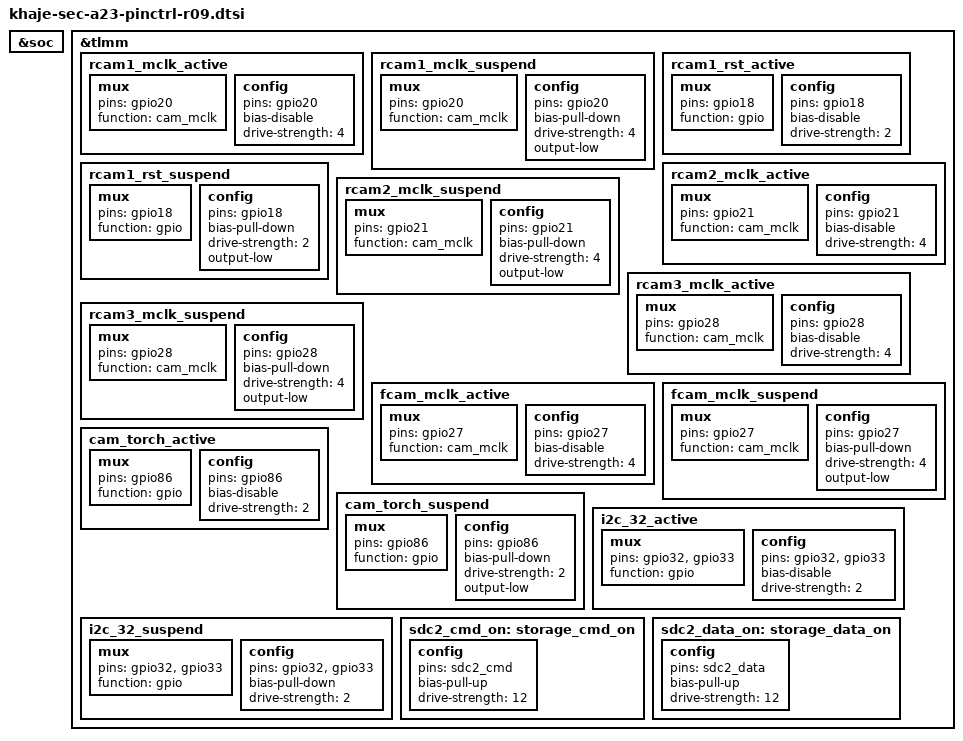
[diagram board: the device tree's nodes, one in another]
/* Copyright (c) 2019, The Linux Foundation. All rights reserved.
 *
 * This program is free software; you can redistribute it and/or modify
 * it under the terms of the GNU General Public License version 2 and
 * only version 2 as published by the Free Software Foundation.
 *
 * This program is distributed in the hope that it will be useful,
 * but WITHOUT ANY WARRANTY; without even the implied warranty of
 * MERCHANTABILITY or FITNESS FOR A PARTICULAR PURPOSE.  See the
 * GNU General Public License for more details.
 */

&soc {

};

&tlmm {

/*
 * RCAM id 0
 */
	rcam1_mclk_active: rcam1_mclk_active {
		/* Main Rear1 MCLK */
		mux {
			pins = "gpio20";
			function = "cam_mclk";
		};
		config {
			pins = "gpio20";
			bias-disable; /* No PULL */
			drive-strength = <4>; /* 4 MA */
		};
	};

	rcam1_mclk_suspend: rcam1_mclk_suspend {
		/* Main Rear1 MCLK */
		mux {
			pins = "gpio20";
			function = "cam_mclk";
		};
		config {
			pins = "gpio20";
			bias-pull-down; /* No PULL */
			drive-strength = <4>; /* 4 MA */
			output-low;
		};
	};

	rcam1_rst_active: rcam1_rst_active {
		/* Main Rear1 RESET */
		mux {
			pins = "gpio18";
			function = "gpio";
		};
		config {
			pins = "gpio18";
			bias-disable; /* No PULL */
			drive-strength = <2>; /* 2 MA */
		};
	};

	rcam1_rst_suspend: rcam1_rst_suspend {
		/* Main Rear1 RESET */
		mux {
			pins = "gpio18";
			function = "gpio";
		};
		config {
			pins = "gpio18";
			bias-pull-down; /* No PULL */
			drive-strength = <2>; /* 2 MA */
			output-low;
		};
	};

/*
 * RCAM id 2
 */
	rcam2_mclk_active: rcam2_mclk_active {
		/* Main Rear2 MCLK */
		mux {
			pins = "gpio21";
			function = "cam_mclk";
		};
		config {
			pins = "gpio21";
			bias-disable; /* No PULL */
			drive-strength = <4>; /* 4 MA */
		};
	};

	rcam2_mclk_suspend: rcam2_mclk_suspend {
		/* Main Rear2 MCLK */
		mux {
			pins = "gpio21";
			function = "cam_mclk";
		};
		config {
			pins = "gpio21";
			bias-pull-down; /* No PULL */
			drive-strength = <4>; /* 4 MA */
			output-low;
		};
	};

	
/*
 * RCAM 3
 */
	rcam3_mclk_active: rcam3_mclk_active {
		/* Main Rear3 MCLK */
		mux {
			pins = "gpio28";
			function = "cam_mclk";
		};
		config {
			pins = "gpio28";
			bias-disable; /* No PULL */
			drive-strength = <4>; /* 4 MA */
		};
	};

	rcam3_mclk_suspend: rcam3_mclk_suspend {
		/* Main Rear3 MCLK */
		mux {
			pins = "gpio28";
			function = "cam_mclk";
		};
		config {
			pins = "gpio28";
			bias-pull-down; /* No PULL */
			drive-strength = <4>; /* 4 MA */
			output-low;
		};
	};



/*
 * RCAM 4
 */
	
	
/*
 * FCAM id 1
 */
	fcam_mclk_active: fcam_mclk_active {
		/* Main FCAM MCLK */
		mux {
			pins = "gpio27";
			function = "cam_mclk";
		};
		config {
			pins = "gpio27";
			bias-disable; /* No PULL */
			drive-strength = <4>; /* 4 MA */
		};
	};

	fcam_mclk_suspend: fcam_mclk_suspend {
		/* Main FCAM MCLK */
		mux {
			pins = "gpio27";
			function = "cam_mclk";
		};
		config {
			pins = "gpio27";
			bias-pull-down; /* No PULL */
			drive-strength = <4>; /* 4 MA */
			output-low;
		};
	};

	cam_torch_active: cam_torch_active {
	/* TORCH, FLASH */
		mux {
			pins = "gpio86";
			function = "gpio";
		};
		config {
			pins = "gpio86";
			bias-disable; /* No PULL */
			drive-strength = <2>; /* 2 MA */
		};
	};

	cam_torch_suspend: cam_torch_suspend {
	/* TORCH, FLASH */
		mux {
			pins = "gpio86";
			function = "gpio";
		};
		config {
			pins = "gpio86";
			bias-pull-down; /* PULL DOWN */
			drive-strength = <2>; /* 2 MA */
                        output-low;
		};
	};

	i2c_32_active: i2c_32_active {
		mux {
			/* OIS SW I2C */
			pins = "gpio32", "gpio33";
			function = "gpio";
		};

		config {
			pins = "gpio32", "gpio33";
			bias-disable; /* PULL UP*/
			drive-strength = <2>; /* 2 MA */
		};
	};

	i2c_32_suspend: i2c_32_suspend {
		mux {
			/* OIS SW I2C */
			pins = "gpio32", "gpio33";
			function = "gpio";
		};

		config {
			pins = "gpio32", "gpio33";
			bias-pull-down; /* PULL DOWN */
			drive-strength = <2>; /* 2 MA */
		};
	};

	sdc2_cmd_on: storage_cmd_on {
		config {
			pins = "sdc2_cmd";
			bias-pull-up;           /* pull up */
			drive-strength = <12>;  /* 12 MA */
		};
	};

	sdc2_data_on: storage_data_on {
		config {
			pins = "sdc2_data";
			bias-pull-up;           /* pull up */
			drive-strength = <12>;  /* 12 MA */
		};
	};
};
